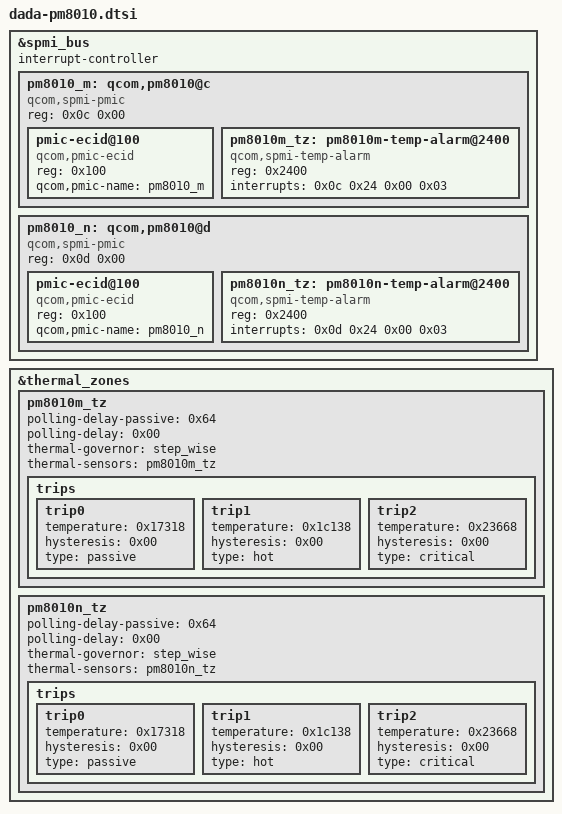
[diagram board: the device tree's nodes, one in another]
// SPDX-License-Identifier: BSD-3-Clause
/*
 * Copyright (c) 2023-2024 Qualcomm Innovation Center, Inc. All rights reserved.
 * Copyright (c) 2025 The LineageOS Project
 */

&spmi_bus {
	#address-cells = <0x02>;
	#size-cells = <0x00>;
	interrupt-controller;
	#interrupt-cells = <0x04>;

	pm8010_m: qcom,pm8010@c {
		compatible = "qcom,spmi-pmic";
		reg = <0x0c 0x00>;
		#address-cells = <0x01>;
		#size-cells = <0x00>;

		pmic-ecid@100 {
			compatible = "qcom,pmic-ecid";
			reg = <0x100>;
			qcom,pmic-name = "pm8010_m";
		};

		pm8010m_tz: pm8010m-temp-alarm@2400 {
			compatible = "qcom,spmi-temp-alarm";
			reg = <0x2400>;
			interrupts = <0x0c 0x24 0x00 0x03>;
			#thermal-sensor-cells = <0x00>;
		};
	};

	pm8010_n: qcom,pm8010@d {
		compatible = "qcom,spmi-pmic";
		reg = <0x0d 0x00>;
		#address-cells = <0x01>;
		#size-cells = <0x00>;

		pmic-ecid@100 {
			compatible = "qcom,pmic-ecid";
			reg = <0x100>;
			qcom,pmic-name = "pm8010_n";
		};

		pm8010n_tz: pm8010n-temp-alarm@2400 {
			compatible = "qcom,spmi-temp-alarm";
			reg = <0x2400>;
			interrupts = <0x0d 0x24 0x00 0x03>;
			#thermal-sensor-cells = <0x00>;
		};
	};
};

&thermal_zones {
	pm8010m_tz {
		polling-delay-passive = <0x64>;
		polling-delay = <0x00>;
		thermal-governor = "step_wise";
		thermal-sensors = <&pm8010m_tz>;

		trips {

			trip0 {
				temperature = <0x17318>;
				hysteresis = <0x00>;
				type = "passive";
			};

			trip1 {
				temperature = <0x1c138>;
				hysteresis = <0x00>;
				type = "hot";
			};

			trip2 {
				temperature = <0x23668>;
				hysteresis = <0x00>;
				type = "critical";
			};
		};
	};

	pm8010n_tz {
		polling-delay-passive = <0x64>;
		polling-delay = <0x00>;
		thermal-governor = "step_wise";
		thermal-sensors = <&pm8010n_tz>;

		trips {

			trip0 {
				temperature = <0x17318>;
				hysteresis = <0x00>;
				type = "passive";
			};

			trip1 {
				temperature = <0x1c138>;
				hysteresis = <0x00>;
				type = "hot";
			};

			trip2 {
				temperature = <0x23668>;
				hysteresis = <0x00>;
				type = "critical";
			};
		};
	};
};
